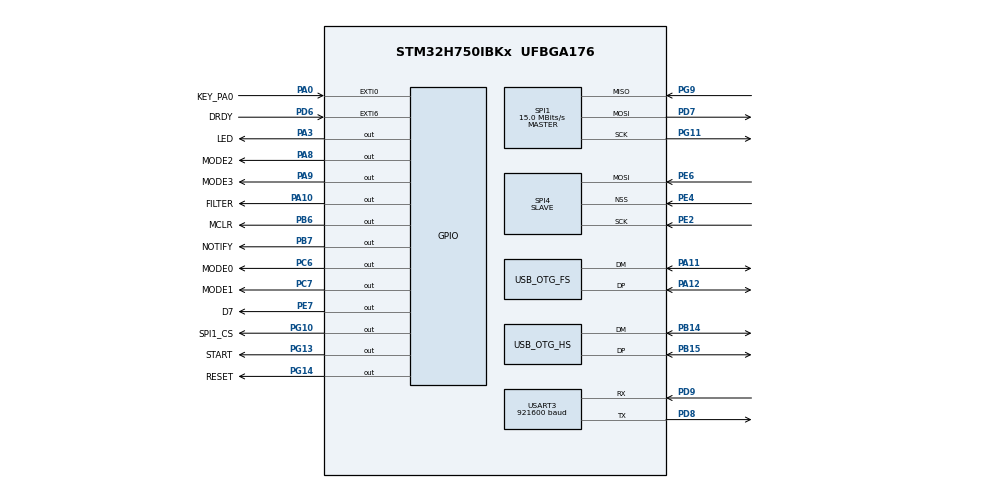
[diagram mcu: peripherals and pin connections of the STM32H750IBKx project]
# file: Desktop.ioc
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Mcu.Family=STM32H7
Mcu.Name=STM32H750IBKx
Mcu.Package=UFBGA176
NVIC.EXTI9_5_IRQn=true\:1\:0\:true\:false\:true\:true\:true\:true
NVIC.OTG_FS_IRQn=true\:0\:0\:false\:false\:true\:false\:true\:true
NVIC.PriorityGroup=NVIC_PRIORITYGROUP_4
NVIC.TIM15_IRQn=true\:10\:0\:true\:false\:true\:true\:true\:true
PA0.GPIO_Label=KEY_PA0
PA0.Signal=GPXTI0
PA10.GPIO_Label=FILTER
PA10.Signal=GPIO_Output
PA11.Mode=Device_Only
PA11.Signal=USB_OTG_FS_DM
PA12.Mode=Device_Only
PA12.Signal=USB_OTG_FS_DP
PA13\ (JTMS/SWDIO).Mode=Serial_Wire
PA13\ (JTMS/SWDIO).Signal=DEBUG_JTMS-SWDIO
PA14\ (JTCK/SWCLK).Mode=Serial_Wire
PA14\ (JTCK/SWCLK).Signal=DEBUG_JTCK-SWCLK
PA3.GPIO_Label=LED
PA3.Signal=GPIO_Output
PA8.GPIO_Label=MODE2
PA8.Signal=GPIO_Output
PA9.GPIO_Label=MODE3
PA9.Signal=GPIO_Output
PB14.Mode=Device_Only_FS
PB14.Signal=USB_OTG_HS_DM
PB15.Mode=Device_Only_FS
PB15.Signal=USB_OTG_HS_DP
PB6.GPIO_Label=MCLR
PB6.Signal=GPIO_Output
PB7.GPIO_Label=NOTIFY
PB7.Signal=GPIO_Output
PC14-OSC32_IN\ (OSC32_IN).Mode=LSE-External-Oscillator
PC14-OSC32_IN\ (OSC32_IN).Signal=RCC_OSC32_IN
PC15-OSC32_OUT\ (OSC32_OUT).Mode=LSE-External-Oscillator
PC15-OSC32_OUT\ (OSC32_OUT).Signal=RCC_OSC32_OUT
PC6.GPIO_Label=MODE0
PC6.Signal=GPIO_Output
PC7.GPIO_Label=MODE1
PC7.Signal=GPIO_Output
PD6.GPIO_Label=DRDY
PD6.Signal=GPXTI6
PD7.Mode=Full_Duplex_Master
PD7.Signal=SPI1_MOSI
PD8.Mode=Asynchronous
PD8.Signal=USART3_TX
PD9.Mode=Asynchronous
PD9.Signal=USART3_RX
PE2.Mode=RX_Only_Simplex_Unidirect_Slave
PE2.Signal=SPI4_SCK
PE4.Mode=NSS_Signal_Hard_Input
PE4.Signal=SPI4_NSS
PE6.Mode=RX_Only_Simplex_Unidirect_Slave
PE6.Signal=SPI4_MOSI
PE7.GPIO_Label=D7
PE7.Signal=GPIO_Output
PG10.GPIO_Label=SPI1_CS
PG10.PinState=GPIO_PIN_SET
PG10.Signal=GPIO_Output
PG11.Mode=Full_Duplex_Master
PG11.Signal=SPI1_SCK
PG13.GPIO_Label=START
PG13.Signal=GPIO_Output
PG14.GPIO_Label=RESET
PG14.GPIO_Speed=GPIO_SPEED_FREQ_LOW
PG14.Signal=GPIO_Output
PG9.Mode=Full_Duplex_Master
PG9.Signal=SPI1_MISO
PH0-OSC_IN\ (PH0).Mode=HSE-External-Oscillator
PH0-OSC_IN\ (PH0).Signal=RCC_OSC_IN
PH1-OSC_OUT\ (PH1).Mode=HSE-External-Oscillator
PH1-OSC_OUT\ (PH1).Signal=RCC_OSC_OUT
ProjectManager.HeapSize=0x200
ProjectManager.StackSize=0x400
ProjectManager.TargetToolchain=MDK-ARM V5.32
RCC.ADCFreq_Value=120000000
RCC.APB1Freq_Value=120000000
RCC.APB2Freq_Value=120000000
RCC.APB3Freq_Value=120000000
RCC.APB4Freq_Value=120000000
RCC.CortexFreq_Value=480000000
RCC.D1PPRE=RCC_APB3_DIV2
RCC.D2PPRE1=RCC_APB1_DIV2
RCC.D2PPRE2=RCC_APB2_DIV2
RCC.D3PPRE=RCC_APB4_DIV2
RCC.DIVM1=1
RCC.DIVM2=1
RCC.DIVM3=4
RCC.DIVN1=120
RCC.DIVN2=120
RCC.DIVN3=260
RCC.DIVP2=8
RCC.DIVP3=4
RCC.DIVQ1=4
RCC.DIVQ3=8
RCC.DIVR1=5
RCC.HCLKFreq_Value=240000000
RCC.HPRE=RCC_HCLK_DIV2
RCC.HSE_VALUE=8000000
RCC.PLLFRACN=0
RCC.PLLSourceVirtual=RCC_PLLSOURCE_HSE
RCC.SAI1CLockSelection=RCC_SAI1CLKSOURCE_PLL3
RCC.SPI123CLockSelection=RCC_SPI123CLKSOURCE_PLL2
RCC.SYSCLKFreq_VALUE=480000000
RCC.SYSCLKSource=RCC_SYSCLKSOURCE_PLLCLK
RCC.USBCLockSelection=RCC_USBCLKSOURCE_PLL3
RCC.USBFreq_Value=65000000
SPI1.BaudRatePrescaler=SPI_BAUDRATEPRESCALER_8
SPI1.CLKPhase=SPI_PHASE_2EDGE
SPI1.CLKPolarity=SPI_POLARITY_HIGH
SPI1.CalculateBaudRate=15.0 MBits/s
SPI1.DataSize=SPI_DATASIZE_8BIT
SPI1.Direction=SPI_DIRECTION_2LINES
SPI1.Mode=SPI_MODE_MASTER
SPI1.NSSPMode=SPI_NSS_PULSE_ENABLE
SPI1.VirtualType=VM_MASTER
SPI4.CLKPolarity=SPI_POLARITY_HIGH
SPI4.DataSize=SPI_DATASIZE_8BIT
SPI4.Direction=SPI_DIRECTION_2LINES_RXONLY
SPI4.Mode=SPI_MODE_SLAVE
SPI4.VirtualNSS=VM_NSSHARD
SPI4.VirtualType=VM_SLAVE
TIM15.AutoReloadPreload=TIM_AUTORELOAD_PRELOAD_ENABLE
TIM15.Period=1000-1
TIM15.Prescaler=240-1
USART3.BaudRate=921600
USART3.VirtualMode-Asynchronous=VM_ASYNC
USB_DEVICE.CLASS_NAME_FS=CDC
USB_DEVICE.VirtualMode-CDC_FS=Cdc
USB_DEVICE.VirtualModeFS=Cdc_FS
USB_OTG_FS.VirtualMode=Device_Only
USB_OTG_HS.VirtualMode-Device_Only_FS=Device_Only_FS
VP_TIM15_VS_ClockSourceINT.Mode=Internal
VP_USB_DEVICE_VS_USB_DEVICE_CDC_FS.Mode=CDC_FS
board=custom

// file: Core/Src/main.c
/* USER CODE BEGIN Header */
/**
  ******************************************************************************
  * @file           : main.c
  * @brief          : Main program body
  ******************************************************************************
  * @attention
  *
  * <h2><center>&copy; Copyright (c) 2023 STMicroelectronics.
  * All rights reserved.</center></h2>
  *
  * This software component is licensed by ST under BSD 3-Clause license,
  * the "License"; You may not use this file except in compliance with the
  * License. You may obtain a copy of the License at:
  *                        opensource.org/licenses/BSD-3-Clause
  *
  ******************************************************************************
  */
/* USER CODE END Header */
#include "main.h"
#include "spi.h"
#include "tim.h"
#include "usart.h"
#include "usb_device.h"
#include "usb_otg_hs.h"
#include "gpio.h"

/* USER CODE BEGIN Includes */
#include "uApp_other.h"
#include "uApp_AD7768.h"
#include "uspi.h"
#include "ugpio.h"
/* USER CODE END Includes */

void SystemClock_Config(void);
void PeriphCommonClock_Config(void);

int main(void)
{

  /* MCU Configuration--------------------------------------------------------*/

  /* Reset of all peripherals, Initializes the Flash interface and the Systick. */
  HAL_Init();

  /* Configure the system clock */
  SystemClock_Config();

/* Configure the peripherals common clocks */
  PeriphCommonClock_Config();

  /* Initialize all configured peripherals */
  MX_GPIO_Init();
  MX_SPI1_Init();
  MX_USART3_UART_Init();
  MX_USB_DEVICE_Init();
  MX_TIM15_Init();
  MX_SPI4_Init();
  MX_USB_OTG_HS_PCD_Init();
  /* USER CODE BEGIN 2 */
	HAL_TIM_Base_Start_IT(&htim15);		//开启系统tick

  /* USER CODE END 2 */

  /* Infinite loop */
  /* USER CODE BEGIN WHILE */
	my_ad7768_init();
  while (1)
  {

    /* USER CODE END WHILE */

  }
}

void SystemClock_Config(void)
{
  RCC_OscInitTypeDef RCC_OscInitStruct = {0};
  RCC_ClkInitTypeDef RCC_ClkInitStruct = {0};

  /** Supply configuration update enable
  */
  HAL_PWREx_ConfigSupply(PWR_LDO_SUPPLY);
  /** Configure the main internal regulator output voltage
  */
  __HAL_PWR_VOLTAGESCALING_CONFIG(PWR_REGULATOR_VOLTAGE_SCALE0);

  while(!__HAL_PWR_GET_FLAG(PWR_FLAG_VOSRDY)) {}
  /** Macro to configure the PLL clock source
  */
  __HAL_RCC_PLL_PLLSOURCE_CONFIG(RCC_PLLSOURCE_HSE);
  /** Initializes the RCC Oscillators according to the specified parameters
  * in the RCC_OscInitTypeDef structure.
  */
  RCC_OscInitStruct.OscillatorType = RCC_OSCILLATORTYPE_HSE;
  RCC_OscInitStruct.HSEState = RCC_HSE_ON;
  RCC_OscInitStruct.PLL.PLLState = RCC_PLL_ON;
  RCC_OscInitStruct.PLL.PLLSource = RCC_PLLSOURCE_HSE;
  RCC_OscInitStruct.PLL.PLLM = 1;
  RCC_OscInitStruct.PLL.PLLN = 120;
  RCC_OscInitStruct.PLL.PLLP = 2;
  RCC_OscInitStruct.PLL.PLLQ = 4;
  RCC_OscInitStruct.PLL.PLLR = 5;
  RCC_OscInitStruct.PLL.PLLRGE = RCC_PLL1VCIRANGE_3;
  RCC_OscInitStruct.PLL.PLLVCOSEL = RCC_PLL1VCOWIDE;
  RCC_OscInitStruct.PLL.PLLFRACN = 0;
  if (HAL_RCC_OscConfig(&RCC_OscInitStruct) != HAL_OK)
  {
    Error_Handler();
  }
  /** Initializes the CPU, AHB and APB buses clocks
  */
  RCC_ClkInitStruct.ClockType = RCC_CLOCKTYPE_HCLK|RCC_CLOCKTYPE_SYSCLK
                              |RCC_CLOCKTYPE_PCLK1|RCC_CLOCKTYPE_PCLK2
                              |RCC_CLOCKTYPE_D3PCLK1|RCC_CLOCKTYPE_D1PCLK1;
  RCC_ClkInitStruct.SYSCLKSource = RCC_SYSCLKSOURCE_PLLCLK;
  RCC_ClkInitStruct.SYSCLKDivider = RCC_SYSCLK_DIV1;
  RCC_ClkInitStruct.AHBCLKDivider = RCC_HCLK_DIV2;
  RCC_ClkInitStruct.APB3CLKDivider = RCC_APB3_DIV2;
  RCC_ClkInitStruct.APB1CLKDivider = RCC_APB1_DIV2;
  RCC_ClkInitStruct.APB2CLKDivider = RCC_APB2_DIV2;
  RCC_ClkInitStruct.APB4CLKDivider = RCC_APB4_DIV2;

  if (HAL_RCC_ClockConfig(&RCC_ClkInitStruct, FLASH_LATENCY_4) != HAL_OK)
  {
    Error_Handler();
  }
}

void PeriphCommonClock_Config(void)
{
  RCC_PeriphCLKInitTypeDef PeriphClkInitStruct = {0};

  /** Initializes the peripherals clock
  */
  PeriphClkInitStruct.PeriphClockSelection = RCC_PERIPHCLK_USB;
  PeriphClkInitStruct.PLL3.PLL3M = 4;
  PeriphClkInitStruct.PLL3.PLL3N = 260;
  PeriphClkInitStruct.PLL3.PLL3P = 4;
  PeriphClkInitStruct.PLL3.PLL3Q = 8;
  PeriphClkInitStruct.PLL3.PLL3R = 2;
  PeriphClkInitStruct.PLL3.PLL3RGE = RCC_PLL3VCIRANGE_1;
  PeriphClkInitStruct.PLL3.PLL3VCOSEL = RCC_PLL3VCOWIDE;
  PeriphClkInitStruct.PLL3.PLL3FRACN = 0;
  PeriphClkInitStruct.UsbClockSelection = RCC_USBCLKSOURCE_PLL3;
  if (HAL_RCCEx_PeriphCLKConfig(&PeriphClkInitStruct) != HAL_OK)
  {
    Error_Handler();
  }
}

/* USER CODE BEGIN 4 */
void HAL_TIM_PeriodElapsedCallback(TIM_HandleTypeDef *htim)
{
  if (htim->Instance == TIM15)
	{ //周期定时tick = 1ms
   	LED_Blinky();					//系统指示灯
  }

}
/* USER CODE END 4 */

void Error_Handler(void)
{
  __disable_irq();
  while (1)
  {
  }
}

/************************ (C) COPYRIGHT STMicroelectronics *****END OF FILE****/
